VERSION ""

NS_ :

BS_:

BU_: Tutorial

BO_ 2566889761 LD: 8 Vector__XXX
 SG_ RightTurnSignalLights : 44|2@1+ (1,0) [0|3] "" Vector__XXX
 SG_ LeftTurnSignalLights : 46|2@1+ (1,0) [0|3] "" Vector__XXX

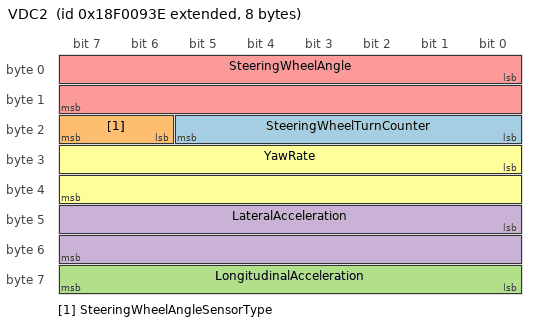
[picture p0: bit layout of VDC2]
BO_ 2565867838 VDC2: 8 Vector__XXX
 SG_ SteeringWheelTurnCounter : 16|6@1+ (1,-32) [-32|29] "turns" Vector__XXX
 SG_ SteeringWheelAngleSensorType : 22|2@1+ (1,0) [0|3] "" Vector__XXX
 SG_ LongitudinalAcceleration : 56|8@1+ (0.1,-12.5) [-12.5|12.5] "m/s²" Vector__XXX
 SG_ LateralAcceleration : 40|16@1+ (0.00048827328612559,-15.687) [-15.687|15.687] "m/s²" Vector__XXX
 SG_ SteeringWheelAngle : 0|16@1+ (0.0559519970879496,-1797.59778644344) [-1797.59778644344|1797.59778644344] "deg" Vector__XXX
 SG_ YawRate : 24|16@1+ (0.00699087882725169,-224.599459522536) [-224.599459522536|224.599459522536] "deg/s" Vector__XXX

BO_ 2365484270 TCO1: 8 Vector__XXX
 SG_ TachographVehicleSpeed : 48|16@1+ (0.0039062485409696,0) [0|250.996] "km/h" Vector__XXX

CM_ SG_ 2566889761 LeftTurnSignalLights "This parameter provides measured data from the tractor and attached implement left turn signal lights.";
BA_DEF_ SG_  "SigType" ENUM  "Default","Range","RangeSigned","ASCII","Discrete","Control","ReferencePGN","DTC","StringDelimiter","StringLength","StringLengthControl","MessageCounter","MessageChecksum";
BA_DEF_ SG_  "GenSigEVName" STRING ;
BA_DEF_ SG_  "GenSigILSupport" ENUM  "No","Yes";
BA_DEF_ SG_  "GenSigSendType" ENUM  "Cyclic","OnWrite","OnWriteWithRepetition","OnChange","OnChangeWithRepetition","IfActive","IfActiveWithRepetition","NoSigSendType";
BA_DEF_ BO_  "GenMsgILSupport" ENUM  "No","Yes";
BA_DEF_ BU_  "NmStationAddress" INT 0 255;
BA_DEF_ BO_  "GenMsgSendType" ENUM  "cyclic","NotUsed","IfActive","NotUsed","NotUsed","NotUsed","NotUsed","NotUsed","noMsgSendType";
BA_DEF_ BO_  "GenMsgRequestable" INT 0 1;
BA_DEF_ BO_  "GenMsgCycleTime" INT 0 3600000;
BA_DEF_  "DBName" STRING ;
BA_DEF_  "BusType" STRING ;
BA_DEF_ BO_  "VFrameFormat" ENUM  "StandardCAN","ExtendedCAN","reserved","J1939PG";
BA_DEF_DEF_  "SigType" "Default";
BA_DEF_DEF_  "GenSigEVName" "Env@Nodename_@Signame";
BA_DEF_DEF_  "GenSigILSupport" "Yes";
BA_DEF_DEF_  "GenSigSendType" "NoSigSendType";
BA_DEF_DEF_  "GenMsgILSupport" "Yes";
BA_DEF_DEF_  "NmStationAddress" 254;
BA_DEF_DEF_  "GenMsgSendType" "noMsgSendType";
BA_DEF_DEF_  "GenMsgRequestable" 1;
BA_DEF_DEF_  "GenMsgCycleTime" 0;
BA_DEF_DEF_  "DBName" "";
BA_DEF_DEF_  "BusType" "CAN";
BA_DEF_DEF_  "VFrameFormat" "J1939PG";
BA_ "DBName" "MAN_2018_TGM_DEG";
BA_ "VFrameFormat" BO_ 2566889761 1;
BA_ "GenMsgSendType" BO_ 2565867838 0;
BA_ "GenMsgCycleTime" BO_ 2565867838 20;
BA_ "GenMsgSendType" BO_ 2365484270 0;
BA_ "GenMsgCycleTime" BO_ 2365484270 50;
BA_ "SigType" SG_ 2566889761 RightTurnSignalLights 4;
BA_ "SigType" SG_ 2566889761 LeftTurnSignalLights 4;
BA_ "SigType" SG_ 2565867838 SteeringWheelAngleSensorType 5;
BA_ "SigType" SG_ 2565867838 LongitudinalAcceleration 1;
BA_ "SigType" SG_ 2565867838 LateralAcceleration 1;
BA_ "SigType" SG_ 2565867838 SteeringWheelAngle 1;
BA_ "SigType" SG_ 2565867838 YawRate 1;
BA_ "SigType" SG_ 2365484270 TachographVehicleSpeed 1;
